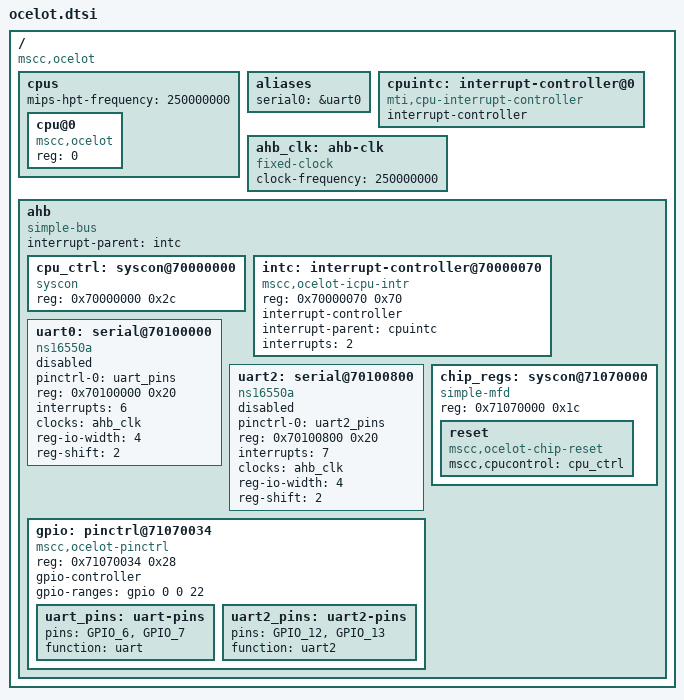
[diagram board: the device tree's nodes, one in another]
/*
 * Copyright (c) 2017 Microsemi Corporation
 *
 * SPDX-License-Identifier: (GPL-2.0 OR MIT)
 */

/ {
	#address-cells = <1>;
	#size-cells = <1>;
	compatible = "mscc,ocelot";

	cpus {
		#address-cells = <1>;
		#size-cells = <0>;

		mips-hpt-frequency = <250000000>;

		cpu@0 {
			compatible = "mscc,ocelot";
			device_type = "cpu";
			reg = <0>;
		};
	};

	aliases {
		serial0 = &uart0;
	};

	cpuintc: interrupt-controller@0 {
		#address-cells = <0>;
		#interrupt-cells = <1>;
		interrupt-controller;
		compatible = "mti,cpu-interrupt-controller";
	};

	ahb_clk: ahb-clk {
		compatible = "fixed-clock";
		#clock-cells = <0>;
		clock-frequency = <250000000>;
	};

	ahb {
		compatible = "simple-bus";
		#address-cells = <1>;
		#size-cells = <1>;
		ranges;

		interrupt-parent = <&intc>;

		cpu_ctrl: syscon@70000000 {
			compatible = "syscon";
			reg = <0x70000000 0x2c>;
		};

		intc: interrupt-controller@70000070 {
			compatible = "mscc,ocelot-icpu-intr";
			reg = <0x70000070 0x70>;
			#interrupt-cells = <1>;
			interrupt-controller;
			interrupt-parent = <&cpuintc>;
			interrupts = <2>;
		};

		uart0: serial@70100000 {
			pinctrl-0 = <&uart_pins>;
			pinctrl-names = "default";
			compatible = "ns16550a";
			reg = <0x70100000 0x20>;
			interrupts = <6>;
			clocks = <&ahb_clk>;
			reg-io-width = <4>;
			reg-shift = <2>;

			status = "disabled";
		};

		uart2: serial@70100800 {
			pinctrl-0 = <&uart2_pins>;
			pinctrl-names = "default";
			compatible = "ns16550a";
			reg = <0x70100800 0x20>;
			interrupts = <7>;
			clocks = <&ahb_clk>;
			reg-io-width = <4>;
			reg-shift = <2>;

			status = "disabled";
		};

		chip_regs: syscon@71070000 {
			compatible = "simple-mfd", "syscon";
			reg = <0x71070000 0x1c>;

			reset {
				compatible = "mscc,ocelot-chip-reset";
				mscc,cpucontrol = <&cpu_ctrl>;
			};
		};

		gpio: pinctrl@71070034 {
			compatible = "mscc,ocelot-pinctrl";
			reg = <0x71070034 0x28>;
			gpio-controller;
			#gpio-cells = <2>;
			gpio-ranges = <&gpio 0 0 22>;

			uart_pins: uart-pins {
				pins = "GPIO_6", "GPIO_7";
				function = "uart";
			};

			uart2_pins: uart2-pins {
				pins = "GPIO_12", "GPIO_13";
				function = "uart2";
			};
		};
	};
};
